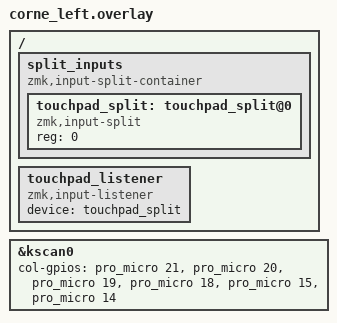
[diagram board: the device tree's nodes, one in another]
/*
 * Copyright (c) 2020 Pete Johanson
 *
 * SPDX-License-Identifier: MIT
 */

#include "corne.dtsi"

&kscan0 {
    col-gpios
        = <&pro_micro 21 GPIO_ACTIVE_HIGH>
        , <&pro_micro 20 GPIO_ACTIVE_HIGH>
        , <&pro_micro 19 GPIO_ACTIVE_HIGH>
        , <&pro_micro 18 GPIO_ACTIVE_HIGH>
        , <&pro_micro 15 GPIO_ACTIVE_HIGH>
        , <&pro_micro 14 GPIO_ACTIVE_HIGH>
        ;
};


/ {
    split_inputs {
        compatible = "zmk,input-split-container";
        #address-cells = <1>;
        #size-cells = <0>;

        /* Matching ID from the peripheral */
        touchpad_split: touchpad_split@0 {
            compatible = "zmk,input-split";
            reg = <0>;
        };
    };

    /* Listener on central side to handle the split events */
    touchpad_listener {
        compatible = "zmk,input-listener";
        device = <&touchpad_split>;
    };
};
